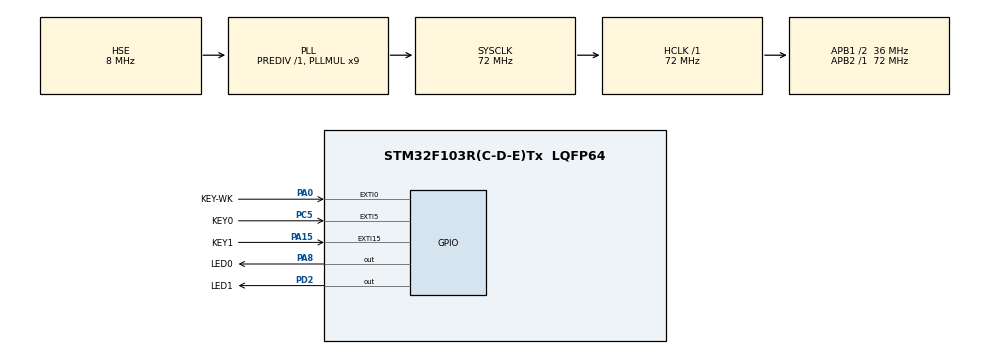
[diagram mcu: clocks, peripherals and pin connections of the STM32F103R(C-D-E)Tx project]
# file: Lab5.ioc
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Mcu.Family=STM32F1
Mcu.Name=STM32F103R(C-D-E)Tx
Mcu.Package=LQFP64
NVIC.EXTI0_IRQn=true\:1\:0\:true\:false\:true\:true\:true\:true
NVIC.EXTI15_10_IRQn=true\:1\:2\:true\:false\:true\:true\:true\:true
NVIC.EXTI9_5_IRQn=true\:1\:1\:true\:false\:true\:true\:true\:true
NVIC.PriorityGroup=NVIC_PRIORITYGROUP_2
PA0-WKUP.GPIO_Label=KEY-WK
PA0-WKUP.GPIO_ModeDefaultEXTI=GPIO_MODE_IT_RISING
PA0-WKUP.GPIO_PuPd=GPIO_PULLDOWN
PA0-WKUP.Signal=GPXTI0
PA13.Mode=Serial_Wire
PA13.Signal=SYS_JTMS-SWDIO
PA14.Mode=Serial_Wire
PA14.Signal=SYS_JTCK-SWCLK
PA15.GPIO_Label=KEY1
PA15.GPIO_ModeDefaultEXTI=GPIO_MODE_IT_FALLING
PA15.GPIO_PuPd=GPIO_PULLUP
PA15.Signal=GPXTI15
PA8.GPIO_Label=LED0
PA8.Signal=GPIO_Output
PC5.GPIO_Label=KEY0
PC5.GPIO_ModeDefaultEXTI=GPIO_MODE_IT_FALLING
PC5.GPIO_PuPd=GPIO_PULLUP
PC5.Signal=GPXTI5
PD0-OSC_IN.Mode=HSE-External-Oscillator
PD0-OSC_IN.Signal=RCC_OSC_IN
PD1-OSC_OUT.Mode=HSE-External-Oscillator
PD1-OSC_OUT.Signal=RCC_OSC_OUT
PD2.GPIO_Label=LED1
PD2.Signal=GPIO_Output
ProjectManager.HeapSize=0x200
ProjectManager.StackSize=0x400
ProjectManager.TargetToolchain=STM32CubeIDE
RCC.AHBFreq_Value=72000000
RCC.APB1CLKDivider=RCC_HCLK_DIV2
RCC.APB1Freq_Value=36000000
RCC.APB1TimFreq_Value=72000000
RCC.APB2Freq_Value=72000000
RCC.APB2TimFreq_Value=72000000
RCC.HCLKFreq_Value=72000000
RCC.PLLMUL=RCC_PLL_MUL9
RCC.PLLSourceVirtual=RCC_PLLSOURCE_HSE
RCC.SYSCLKFreq_VALUE=72000000
RCC.SYSCLKSource=RCC_SYSCLKSOURCE_PLLCLK
RCC.USBFreq_Value=72000000
board=custom

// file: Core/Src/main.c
/* USER CODE BEGIN Header */
/**
  ******************************************************************************
  * @file           : main.c
  * @brief          : Main program body
  ******************************************************************************
  * @attention
  *
  * Copyright (c) 2023 STMicroelectronics.
  * All rights reserved.
  *
  * This software is licensed under terms that can be found in the LICENSE file
  * in the root directory of this software component.
  * If no LICENSE file comes with this software, it is provided AS-IS.
  *
  ******************************************************************************
  */
/* USER CODE END Header */
#include "main.h"
#include "gpio.h"

/* USER CODE BEGIN Includes */
#include "lcd.h"
/* USER CODE END Includes */

void SystemClock_Config(void);

int main(void)
{

  /* MCU Configuration--------------------------------------------------------*/

  /* Reset of all peripherals, Initializes the Flash interface and the Systick. */
  HAL_Init();

  /* Configure the system clock */
  SystemClock_Config();

  /* USER CODE BEGIN SysInit */
  LCD_Init();
  /* USER CODE END SysInit */

  /* Initialize all configured peripherals */
  MX_GPIO_Init();

  /* Infinite loop */
  /* USER CODE BEGIN WHILE */
  uint8_t x = 0;
  while (1)
  {
    /* USER CODE END WHILE */
	  switch (x) {
		  case 0: LCD_Clear(WHITE); BACK_COLOR = WHITE; break;
		  case 1: LCD_Clear(BLACK); BACK_COLOR = BLACK; break;
		  case 2: LCD_Clear(BLUE); BACK_COLOR = BLUE; break;
		  case 3: LCD_Clear(RED); BACK_COLOR = RED; break;
		  case 4: LCD_Clear(MAGENTA); BACK_COLOR = MAGENTA; break;
		  case 5: LCD_Clear(GREEN); BACK_COLOR = GREEN; break;
		  case 6: LCD_Clear(CYAN); BACK_COLOR = CYAN; break;
		  case 7: LCD_Clear(YELLOW); BACK_COLOR = YELLOW; break;
		  case 8: LCD_Clear(BRRED); BACK_COLOR = BRRED; break;
		  case 9: LCD_Clear(GRAY); BACK_COLOR = GRAY; break;
		  case 10: LCD_Clear(LGRAY); BACK_COLOR = LGRAY; break;
		  case 11: LCD_Clear(BROWN); BACK_COLOR = BROWN; break;
	  }

	  POINT_COLOR = RED;
//	  LCD_ShowString(30, 40, 200, 24, 24, (uint8_t*) "Mini STM32 ^_^");
//	  LCD_ShowString(30, 70, 200, 16, 16, (uint8_t*) "TFTLCD TEST");
	  /* Code of showing address of GPIOA->CRL (represented in hexadecimal) BEGIN */
//	  char str[50];
//	  sprintf(str, "addr = %p", &GPIOA->CRL);

//	  LCD_ShowString(30, 100, 200, 16, 16, str);
//	  /* Code of showing address of GPIOA->CRL (represented in hexadecimal) END */
//	  POINT_COLOR = BLACK;
//	  LCD_DrawRectangle(30, 150, 210, 190);
//	  LCD_Fill(31, 151, 209, 189, YELLOW);
	  x++;
	  if (x == 12)
		  x = 0;
	  HAL_Delay(2000);

  }
}

void SystemClock_Config(void)
{
  RCC_OscInitTypeDef RCC_OscInitStruct = {0};
  RCC_ClkInitTypeDef RCC_ClkInitStruct = {0};

  /** Initializes the RCC Oscillators according to the specified parameters
  * in the RCC_OscInitTypeDef structure.
  */
  RCC_OscInitStruct.OscillatorType = RCC_OSCILLATORTYPE_HSE;
  RCC_OscInitStruct.HSEState = RCC_HSE_ON;
  RCC_OscInitStruct.HSEPredivValue = RCC_HSE_PREDIV_DIV1;
  RCC_OscInitStruct.HSIState = RCC_HSI_ON;
  RCC_OscInitStruct.PLL.PLLState = RCC_PLL_ON;
  RCC_OscInitStruct.PLL.PLLSource = RCC_PLLSOURCE_HSE;
  RCC_OscInitStruct.PLL.PLLMUL = RCC_PLL_MUL9;
  if (HAL_RCC_OscConfig(&RCC_OscInitStruct) != HAL_OK)
  {
    Error_Handler();
  }

  /** Initializes the CPU, AHB and APB buses clocks
  */
  RCC_ClkInitStruct.ClockType = RCC_CLOCKTYPE_HCLK|RCC_CLOCKTYPE_SYSCLK
                              |RCC_CLOCKTYPE_PCLK1|RCC_CLOCKTYPE_PCLK2;
  RCC_ClkInitStruct.SYSCLKSource = RCC_SYSCLKSOURCE_PLLCLK;
  RCC_ClkInitStruct.AHBCLKDivider = RCC_SYSCLK_DIV1;
  RCC_ClkInitStruct.APB1CLKDivider = RCC_HCLK_DIV2;
  RCC_ClkInitStruct.APB2CLKDivider = RCC_HCLK_DIV1;

  if (HAL_RCC_ClockConfig(&RCC_ClkInitStruct, FLASH_LATENCY_2) != HAL_OK)
  {
    Error_Handler();
  }
}

void Error_Handler(void)
{
  __disable_irq();
  while (1)
  {
  }
}
